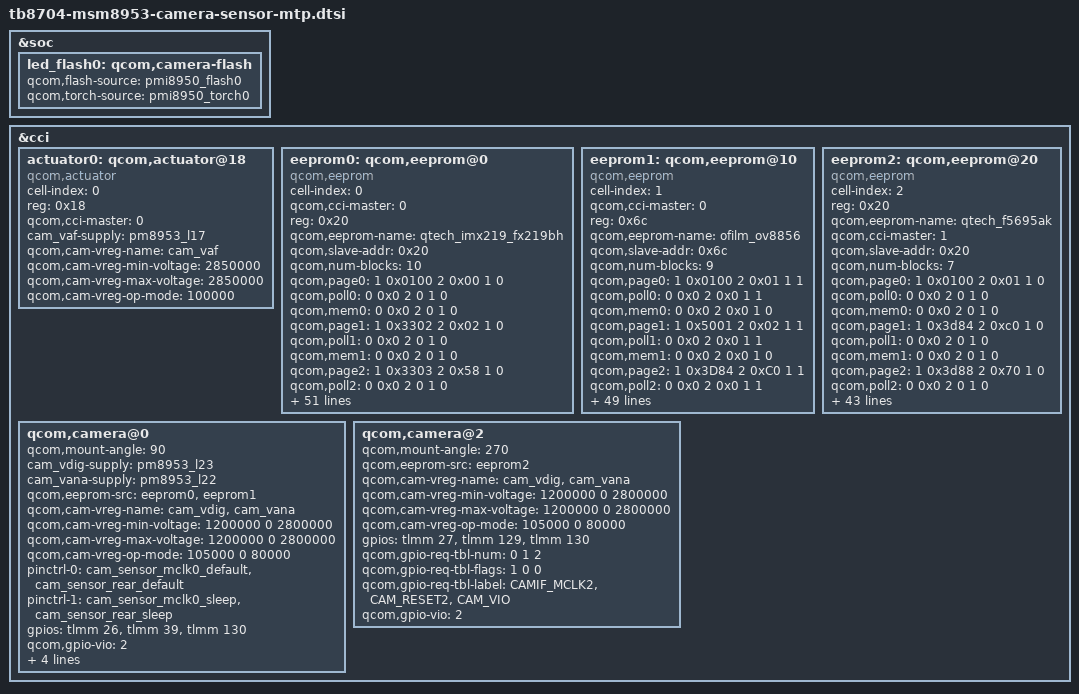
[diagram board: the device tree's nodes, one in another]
/*
 * Copyright (c) 2015-2016, The Linux Foundation. All rights reserved.
 *
 * This program is free software; you can redistribute it and/or modify
 * it under the terms of the GNU General Public License version 2 and
 * only version 2 as published by the Free Software Foundation.
 *
 * This program is distributed in the hope that it will be useful,
 * but WITHOUT ANY WARRANTY; without even the implied warranty of
 * MERCHANTABILITY or FITNESS FOR A PARTICULAR PURPOSE.  See the
 * GNU General Public License for more details.
 */

&soc {
	led_flash0: qcom,camera-flash {
		qcom,flash-source = <&pmi8950_flash0 >;
		qcom,torch-source = <&pmi8950_torch0 >;
	};
};

&cci {
	actuator0: qcom,actuator@18 {
		cell-index = <0>;
		reg = <0x18>;
		compatible = "qcom,actuator";
		qcom,cci-master = <0>;
		cam_vaf-supply = <&pm8953_l17>;
		qcom,cam-vreg-name = "cam_vaf";
		qcom,cam-vreg-min-voltage = <2850000>;
		qcom,cam-vreg-max-voltage = <2850000>;
		qcom,cam-vreg-op-mode = <100000>;
	};
	
	/delete-node/ qcom,actuator@0;
	/delete-node/ qcom,actuator@1;

	eeprom0: qcom,eeprom@0 {
		cell-index = <0>;
		compatible = "qcom,eeprom";
		qcom,cci-master = <0>;
		reg = <0x20>;
		qcom,eeprom-name = "qtech_imx219_fx219bh";
		qcom,slave-addr = <0x20>;
		qcom,num-blocks = <10>;

		qcom,page0 = <1 0x0100 2 0x00 1 0>;//Standby mode
		qcom,poll0 = <0 0x0 2 0 1 0>;
		qcom,mem0 = <0 0x0 2 0 1 0>;

		qcom,page1 = <1 0x3302 2 0x02 1 0>;//set OTP write clock setting
		qcom,poll1 = <0 0x0 2 0 1 0>;
		qcom,mem1 = <0 0x0 2 0 1 0>;

		qcom,page2 = <1 0x3303 2 0x58 1 0>;//set OTP write clock setting
		qcom,poll2 = <0 0x0 2 0 1 0>;
		qcom,mem2 = <0 0x0 2 0 1 0>;

		qcom,page3 = <1 0x012A 2 0x18 1 0>;//set input clock frequency
		qcom,poll3 = <0 0x0 2 0 1 0>;
		qcom,mem3 = <0 0x0 2 0 1 0>;

		qcom,page4 = <1 0x012B 2 0x00 1 0>;//set input clock frequency
		qcom,poll4 = <0 0x0 2 0 1 0>;
		qcom,mem4 = <0 0x0 2 0 1 0>;

		qcom,page5 = <1 0x3300 2 0x08 1 0>;//ECC OFF
		qcom,poll5 = <0 0x0 2 0 1 0>;
		qcom,mem5 = <0 0x0 2 0 1 0>;

		qcom,page6 = <1 0x3200 2 0x01 1 1>;//Page Read Enable
		qcom,poll6 = <0 0x3201 2 0x01 1 0>;//wait until ready to read
		qcom,mem6 = <0 0x0 2 0 1 0>;

		qcom,page7 = <1 0x3202 2 0x00 1 1>;//set page number=0
		qcom,poll7 = <0 0x3201 2 0x01 1 0>;
		qcom,mem7 = <64 0x3204 2 0 1 1>;//read page 0

		qcom,page8 = <1 0x3202 2 0x01 1 1>;//set page number=1
		qcom,poll8 = <0 0x3201 2 0x01 1 0>;
		qcom,mem8 = <64 0x3204 2 0 1 1>;//read page 1

		qcom,page9 = <1 0x3202 2 0x02 1 1>;//set page number=2
		qcom,poll9 = <0 0x3201 2 0x01 1 0>;
		qcom,mem9 = <64 0x3204 2 0 1 1>;//read page 2

		cam_vdig-supply = <&pm8953_l23>;
		cam_vana-supply = <&pm8953_l22>;
		qcom,cam-vreg-name = "cam_vdig", "cam_vana";
		qcom,cam-vreg-min-voltage = <1200000 0 2800000>;
		qcom,cam-vreg-max-voltage = <1200000 0 2800000>;
		qcom,cam-vreg-op-mode = <105000 0 80000>;
		pinctrl-names = "cam_default", "cam_suspend";
		pinctrl-0 = <&cam_sensor_mclk0_default
				&cam_sensor_rear_default>;
		pinctrl-1 = <&cam_sensor_mclk0_sleep
				&cam_sensor_rear_sleep>;
		gpios = <&tlmm 26 0>,
			<&tlmm 39 0>,
			<&tlmm 130 0>;
		qcom,gpio-reset = <1>;
		qcom,gpio-vio = <2>;
		qcom,gpio-req-tbl-num = <0 1 2>;
		qcom,gpio-req-tbl-flags = <1 0 0>;
		qcom,gpio-req-tbl-label = "CAMIF_MCLK0", "CAM_RESET0", "CAM_VIO";
		qcom,sensor-mode = <0>;
		status = "ok";

		qcom,cam-power-seq-type = "sensor_gpio",
					"sensor_vreg",
					"sensor_vreg",
					"sensor_clk",
					"sensor_gpio";
		
		qcom,cam-power-seq-val = "sensor_gpio_vio",
					"cam_vana",
					"cam_vdig",
					"sensor_cam_mclk",
					"sensor_gpio_reset";
		qcom,cam-power-seq-cfg-val = <1 1 1 24000000 1>;
		qcom,cam-power-seq-delay = <0 0 1 10 1>;
		clocks = <&clock_gcc clk_mclk0_clk_src>,
				<&clock_gcc clk_gcc_camss_mclk0_clk>;
		clock-names = "cam_src_clk", "cam_clk";
		qcom,clock-rates = <19200000 0>;
		/delete-property/ qcom,gpio-standby;
		/delete-property/ qcom,gpio-vana;
		/delete-property/ cam_vaf-supply;
		/delete-property/ cam_vio-supply;
	};
	/delete-node/ qcom,eeprom@1;
	/delete-node/ qcom,eeprom@2;

	eeprom1: qcom,eeprom@10{
                   cell-index = <1>;
                   compatible = "qcom,eeprom";
                   qcom,cci-master = <0>;
                   reg = <0x6c>;
   //add  jack  start
                   qcom,eeprom-name = "ofilm_ov8856"; //add
                   qcom,slave-addr = <0x6c>;          //add accoring to the camera address                                            
                   qcom,num-blocks = <9>;             //add
 
                   qcom,page0 = <1 0x0100 2 0x01 1 1>;//add, write
                   qcom,poll0 = <0 0x0 2 0x0 1 1>;
                   qcom,mem0  = <0 0x0 2 0x0 1 0>;//read
                   
                   qcom,page1 = <1 0x5001 2 0x02 1 1>;//modify
                   qcom,poll1 = <0 0x0 2 0x0 1 1>;
                   qcom,mem1  = <0 0x0 2 0x0 1 0>;
 
                   qcom,page2 = <1 0x3D84 2 0xC0 1 1>;//modify
	   qcom,poll2 = <0 0x0 2 0x0 1 1>;
	   qcom,mem2  = <0 0x0 2 0x0 1 0>;

	   qcom,page3 = <1 0x3D88 2 0x70 1 1>;
	   qcom,poll3 = <0 0x0 2 0x0 1 1>;
	   qcom,mem3  = <0 0x0 2 0x0 1 0>;

	   qcom,page4 = <1 0x3d89 2 0x10 1 1>;
	   qcom,poll4 = <0 0x0 2 0x0 1 1>;
	   qcom,mem4  = <0 0x0 2 0x0 1 0>;

	   qcom,page5 = <1 0x3d8A 2 0x72 1 0>;
	   qcom,poll5 = <0 0x0 2 0x0 1 1>;
	   qcom,mem5  = <0 0x0 2 0x0 1 0>;

	   qcom,page6 = <1 0x3D8B 2 0x0a 1 0x0a>;
	   qcom,poll6 = <0 0x0 2 0x0 1 1>;
	   qcom,mem6 =  <0 0x0 2 0x0 1 0>;
         
	    qcom,page7 = <1 0x3D81 2 0x01 1 10>;
	   qcom,poll7 = <0 0x0 2 0x0 1 1>;
	   qcom,mem7  = <512 0x7010 2 0x0 1 5>;
 
	    qcom,page8 = <1 20481 2 10 1 5>;
	    qcom,pageen8 = <0x1 0x100 0x2 0x0 0x1 0x5>;
	   qcom,poll8 = <0 0x0 2 0x0 1 1>;
	   qcom,mem8  = <0 0 2 0 1 0>;

                 cam_vdig-supply = <&pm8953_l2>;
                 cam_vana-supply = <&pm8953_l22>;
                 qcom,cam-vreg-name = "cam_vdig", "cam_vana";
                 qcom,cam-vreg-min-voltage = <1200000 0 2800000>;
                 qcom,cam-vreg-max-voltage = <1200000 0 2800000>;
                 qcom,cam-vreg-op-mode = <105000 0 80000>;
                 pinctrl-names = "cam_default", "cam_suspend";
                 pinctrl-0 = <&cam_sensor_mclk0_default
                                                 &cam_sensor_rear_default>;
                 pinctrl-1 = <&cam_sensor_mclk0_sleep &cam_sensor_rear_sleep>;
                 gpios = <&tlmm 26 0>,
                         <&tlmm 39 0>,
                         <&tlmm 130 0>;
                 qcom,gpio-reset = <1>;
                 qcom,sensor-mode = <0>;
                 qcom,gpio-vio = <2>;
                 qcom,gpio-req-tbl-num = <0 1 2>;
                 qcom,gpio-req-tbl-flags = <1 0 0>;
                 qcom,gpio-req-tbl-label = "CAMIF_MCLK0", "CAM_RESET0", "CAM_VIO";
                 qcom,cam-power-seq-type = "sensor_gpio", "sensor_vreg", "sensor_vreg", "sensor_clk", "sensor_gpio";
                 qcom,cam-power-seq-val =  "sensor_gpio_vio", "cam_vana", "cam_vdig", "sensor_cam_mclk", "sensor_gpio_reset";
                 qcom,cam-power-seq-cfg-val = <1 1 1 24000000 1>;
                 qcom,cam-power-seq-delay = <0 0 1 10 1>;
                 status = "ok";
                 clocks = <&clock_gcc clk_mclk0_clk_src>,
                                 <&clock_gcc clk_gcc_camss_mclk0_clk>;
                 clock-names = "cam_src_clk", "cam_clk";
                 qcom,clock-rates = <19200000 0>;

	};
	eeprom2: qcom,eeprom@20 {
		cell-index = <2>;
		reg = <0x20>;
		qcom,eeprom-name = "qtech_f5695ak";
		compatible = "qcom,eeprom";
		qcom,cci-master = <1>;
		qcom,slave-addr = <0x20>;
		qcom,num-blocks = <7>;

		qcom,page0 = <1 0x0100 2 0x01 1 0>;//Stream on mode
		qcom,poll0 = <0 0x0 2 0 1 0>;
		qcom,mem0 = <0 0x0 2 0 1 0>;

		qcom,page1 = <1 0x3d84 2 0xc0 1 0>;//manual made
		qcom,poll1 = <0 0x0 2 0 1 0>;
		qcom,mem1 = <0 0x0 2 0 1 0>;

		qcom,page2 = <1 0x3d88 2 0x70 1 0>;//star address high
		qcom,poll2 = <0 0x0 2 0 1 0>;
		qcom,mem2 = <0 0x0 2 0 1 0>;

		qcom,page3 = <1 0x3d89 2 0x0c 1 0>;//star address low
		qcom,poll3 = <0 0x0 2 0 1 0>;
		qcom,mem3 = <0 0x0 2 0 1 0>;

		qcom,page4 = <1 0x3d8a 2 0x70 1 0>;//end address high
		qcom,poll4 = <0 0x0 2 0 1 0>;
		qcom,mem4 = <0 0x0 2 0 1 0>;

		qcom,page5 = <1 0x3d8b 2 0x1b 1 0>;//end address low
		qcom,poll5 = <0 0x0 2 0 1 0>;
		qcom,mem5 = <0 0x0 2 0 1 0>;

		qcom,page6 = <1 0x3d81 2 0x01 1 10>;//Page Read Enable
		qcom,poll6 = <0 0x0 2 0 1 0>;
		qcom,mem6 = <16 0x700c 2 0 1 0>;//read 

		cam_vdig-supply = <&pm8953_l23>;
		cam_vana-supply = <&pm8953_l22>;
		qcom,cam-vreg-name = "cam_vdig", "cam_vana";
		qcom,cam-vreg-min-voltage = <1175000 0 2800000>;
		qcom,cam-vreg-max-voltage = <1175000 0 2800000>;
		qcom,cam-vreg-op-mode = <105000 0 80000>;
		qcom,gpio-no-mux = <0>;
		pinctrl-names = "cam_default", "cam_suspend";
		pinctrl-0 = <&cam_sensor_mclk1_default
				&cam_sensor_front1_default>;
		pinctrl-1 = <&cam_sensor_mclk1_sleep
				&cam_sensor_front1_sleep>;
		gpios = <&tlmm 27 0>,
			<&tlmm 129 0>,
			<&tlmm 130 0>;
		qcom,gpio-reset = <1>;
		qcom,gpio-vio = <2>;
		qcom,gpio-req-tbl-num = <0 1 2>;
		qcom,gpio-req-tbl-flags = <1 0 0>;
		qcom,gpio-req-tbl-label = "CAMIF_MCLK2", "CAM_RESET2", "CAM_VIO";
		qcom,sensor-mode = <0>;
		status = "ok";

		qcom,cam-power-seq-type = "sensor_gpio", "sensor_vreg", "sensor_vreg", "sensor_clk", "sensor_gpio";
		qcom,cam-power-seq-val = "sensor_gpio_vio", "cam_vana", "cam_vdig", "sensor_cam_mclk", "sensor_gpio_reset";
		qcom,cam-power-seq-cfg-val = <1 1 1 24000000 1>;
		qcom,cam-power-seq-delay = <0 0 1 10 1>;
		clocks = <&clock_gcc clk_mclk1_clk_src>,
			<&clock_gcc clk_gcc_camss_mclk1_clk>;
		clock-names = "cam_src_clk", "cam_clk";
		qcom,clock-rates = <19200000 0>;
	};

	//Imx219
	qcom,camera@0 {
		qcom,mount-angle = <90>;
		cam_vdig-supply = <&pm8953_l23>;
		cam_vana-supply = <&pm8953_l22>;
		qcom,eeprom-src = <&eeprom0 &eeprom1>;
		/delete-property/ cam_vaf-supply;
		/delete-property/ cam_vio-supply;
		qcom,cam-vreg-name = "cam_vdig", "cam_vana";
		qcom,cam-vreg-min-voltage = <1200000 0 2800000>;
		qcom,cam-vreg-max-voltage = <1200000 0 2800000>;
		qcom,cam-vreg-op-mode = <105000 0 80000>;
		pinctrl-0 = <&cam_sensor_mclk0_default
				&cam_sensor_rear_default>;
		pinctrl-1 = <&cam_sensor_mclk0_sleep
				&cam_sensor_rear_sleep>;
		gpios = <&tlmm 26 0>,
			<&tlmm 39 0>,
			<&tlmm 130 0>;
		qcom,gpio-vio = <2>;
		qcom,gpio-req-tbl-num = <0 1 2>;
		qcom,gpio-req-tbl-flags = <1 0 0>;
		qcom,gpio-req-tbl-label =  "CAMIF_MCLK0", "CAM_RESET0", "CAM_VIO";
		/delete-property/ qcom,gpio-standby;
		/delete-property/ qcom,gpio-vana;
	};
	
	/delete-node/ qcom,camera@1;

	//OV5695
	qcom,camera@2 {
		qcom,mount-angle = <270>;
		qcom,eeprom-src = <&eeprom2>;
		/delete-property/ qcom,actuator-src;
		/delete-property/ cam_vaf-supply;
		/delete-property/ cam_vio-supply;
		qcom,cam-vreg-name =  "cam_vdig", "cam_vana";
		qcom,cam-vreg-min-voltage = <1200000 0 2800000>;
		qcom,cam-vreg-max-voltage = <1200000 0 2800000>;
		qcom,cam-vreg-op-mode = <105000 0 80000>;
		gpios = <&tlmm 27 0>,
			<&tlmm 129 0>,
			<&tlmm 130 0>;
		qcom,gpio-req-tbl-num = <0 1 2>;
		qcom,gpio-req-tbl-flags = <1 0 0>;
		qcom,gpio-req-tbl-label = "CAMIF_MCLK2", "CAM_RESET2", "CAM_VIO";
		qcom,gpio-vio = <2>;
		/delete-property/ qcom,gpio-standby;
	};
};
